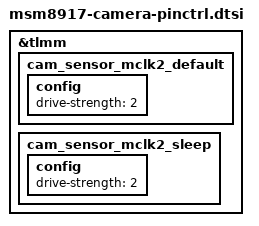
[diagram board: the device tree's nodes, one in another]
/*
 * Copyright (c) 2015-2018, The Linux Foundation. All rights reserved.
 *
 * This program is free software; you can redistribute it and/or modify
 * it under the terms of the GNU General Public License version 2 and
 * only version 2 as published by the Free Software Foundation.
 *
 * This program is distributed in the hope that it will be useful,
 * but WITHOUT ANY WARRANTY; without even the implied warranty of
 * MERCHANTABILITY or FITNESS FOR A PARTICULAR PURPOSE.  See the
 * GNU General Public License for more details.
 */

&tlmm {
	cam_sensor_mclk2_default: cam_sensor_mclk2_default {
		config {
			drive-strength = <2>; /* 2 MA */
		};
	};

	cam_sensor_mclk2_sleep: cam_sensor_mclk2_sleep {
		config {
			drive-strength = <2>; /* 2 MA */
		};
	};
};
